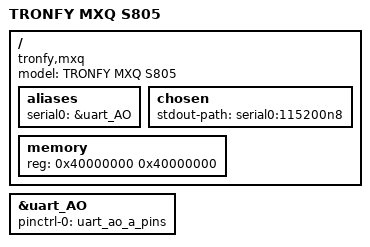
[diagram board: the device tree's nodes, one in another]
// SPDX-License-Identifier: GPL-2.0 OR X11
/*
 * Copyright 2015 Endless Mobile, Inc.
 * Author: Carlo Caione <carlo@endlessm.com>
 */

/dts-v1/;
#include "meson8b.dtsi"

/ {
	model = "TRONFY MXQ S805";
	compatible = "tronfy,mxq", "amlogic,meson8b";

	aliases {
		serial0 = &uart_AO;
	};

	chosen {
		stdout-path = "serial0:115200n8";
	};

	memory {
		device_type = "memory";
		reg = <0x40000000 0x40000000>;
	};
};

&uart_AO {
	status = "okay";
	pinctrl-0 = <&uart_ao_a_pins>;
	pinctrl-names = "default";
};
